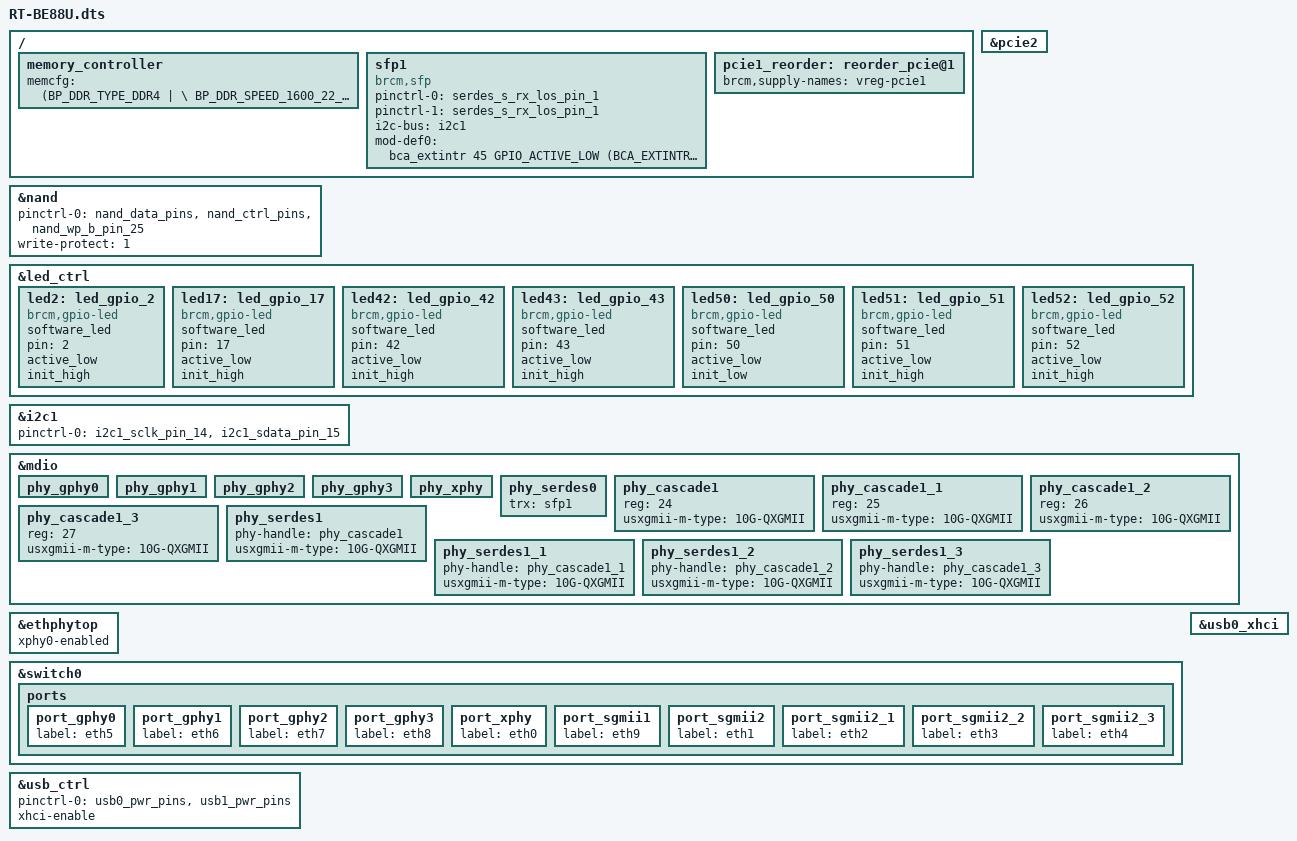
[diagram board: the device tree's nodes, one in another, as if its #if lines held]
#include "6813.dtsi"

/ {
	memory_controller {
		memcfg = <(BP_DDR_TYPE_DDR4       | \
			BP_DDR_SPEED_1600_22_22_22    | \
			BP_DDR_TOTAL_SIZE_2048MB      | \
			BP_DDR_DEVICE_WIDTH_16        | \
			BP_DDR_TOTAL_WIDTH_16BIT      | \
			BP_DDR_TEMP_EXTENDED_ASR      | \
			BP_DDR_SSC_CONFIG_1)>;
	};
/*
    buttons: buttons {
        compatible = "brcm,buttons";
        reset_button {
            ext_irq = <&bca_extintr 13 GPIO_ACTIVE_LOW (BCA_EXTINTR_TYPE_LOW_LEVEL | BCA_EXTINTR_TYPE_SENSE_EDGE)>;
            press {
                print = "Button Press -- Hold for 5s to do restore to default";
            };
            hold {
                rst_to_dflt = <5>;
            };
            release {
                reset = <0>;
            };
        };
        ses_button {
            ext_irq = <&bca_extintr 12 GPIO_ACTIVE_LOW (BCA_EXTINTR_TYPE_LOW_LEVEL | BCA_EXTINTR_TYPE_SENSE_EDGE)>;
            release {
                ses_short_period = <0>;
                ses_long_period = <3>;
            };
        };
    };
*/

    sfp1: sfp1 {
        compatible = "brcm,sfp";
        pinctrl-names = "default", "rx-sd";
        pinctrl-0 = <&serdes_s_rx_los_pin_1>;
        pinctrl-1 = <&serdes_s_rx_los_pin_1>;

        i2c-bus = <&i2c1>;
        mod-def0 = <&bca_extintr 45 GPIO_ACTIVE_LOW (BCA_EXTINTR_TYPE_BOTH_EDGE | BCA_EXTINTR_TYPE_SENSE_EDGE)>;
    };
};

#if defined(CONFIG_BCM_PCIE_HCD) || defined(CONFIG_BCM_PCIE_HCD_MODULE)
#if defined(CONFIG_REGULATOR) && defined(CONFIG_REGULATOR_FIXED_VOLTAGE)
/**********************************************************************/
/* GPIO: Add one define per GPIO (individual or shared) regulator     */
/*       - Skip if no GPIO regulators in use                          */
/**********************************************************************/
#define PCIE1_REG_GPIO    5     /* 5G: SLEEP_1 for vreg_pcie1 node */
#define PCIE2_REG_GPIO    19    /* 2G SLEEP_2 for vreg_pcie2 node */

#include "../bcm_wlan_regulator.dtsi"

/delete-node/ &pcie1;

/ {
    /* pcie core 1 */
    pcie1_reorder: reorder_pcie@1 {
        #define PCIE_ID				1
        #define PCIE_SPI			69
        #define PCIE_ADDR			0x80090000
        #define PCIE_SIZE			PCIE1_REG_SIZE
        #define PCIE_RANGE_ADDR		0xD0000000
        #define PCIE_RANGE_SIZE		0x10000000
        #include "../ip/bcm_pcie_core.dtsi"
    };
};

&pcie1_reorder {
	brcm,supply-names = "vreg-pcie1";
	status = "okay";
};
 
&pcie2 {
	status = "okay";
};
#endif //defined(CONFIG_REGULATOR) && defined(CONFIG_REGULATOR_FIXED_VOLTAGE)
#endif //#if defined(CONFIG_BCM_PCIE_HCD) || defined(CONFIG_BCM_PCIE_HCD_MODULE)

&nand {
	pinctrl-0 = <&nand_data_pins &nand_ctrl_pins &nand_wp_b_pin_25>;
	write-protect = <1>;
	status = "okay";
};

&led_ctrl {
	status="okay";

	/* GPIO LED */
	/* LAN LED */
	led2:led_gpio_2 {
		compatible = "brcm,gpio-led";
		software_led;
		pin = <2>;
		active_low;
		init_high;
	};
	/* 10G WHITE LED */
	led17:led_gpio_17 {
		compatible = "brcm,gpio-led";
		software_led;
		pin = <17>;
		active_low;
		init_high;
	};
	/* WAN WHITE LED */
	led42:led_gpio_42 {
		compatible = "brcm,gpio-led";
		software_led;
		pin = <42>;
		active_low;
		init_high;
	};
	/* WAN RED LED */
	led43:led_gpio_43 {
		compatible = "brcm,gpio-led";
		software_led;
		pin = <43>;
		active_low;
		init_high;
	};
	/* POWER LED */
	led50:led_gpio_50 {
		compatible = "brcm,gpio-led";
		software_led;
		pin = <50>;
		active_low;
		init_low;
	};
	/* USB LED */
	led51:led_gpio_51 {
		compatible = "brcm,gpio-led";
		software_led;
		pin = <51>;
		active_low;
		init_high;
	};
	/* SFP+ LED */
	led52:led_gpio_52 {
		compatible = "brcm,gpio-led";
		software_led;
		pin = <52>;
		active_low;
		init_high;
	};

	/* 2G PA DETECT */
//	led48:led_gpio_48 {
//		compatible = "brcm,gpio-led";
//		software_led;
//		pin = <48>;
//	};

	/* 5G PA DETECT */
//	led53:led_gpio_53 {
///		compatible = "brcm,gpio-led";
//		software_led;
//		pin = <53>;
//	};
};

&i2c1 {
	pinctrl-names = "default";
	pinctrl-0 = <&i2c1_sclk_pin_14 &i2c1_sdata_pin_15>;
	status = "okay";
};

&mdio {
    /* Port PHY mapping:
        port_gphy0 <----> phy_gphy0
        port_gphy1 <----> phy_gphy1
        port_gphy2 <----> phy_gphy2
        port_gphy3 <----> phy_gphy3
        port_xphy <-----> phy_xphy      - Internal 10G PHY
        port_sgmii1 <---> phy_serdes0   - SFP+
        port_sgmii2 <---> phy_serdes1   - phy_cascade1
        port_sgmii2_1 <-> phy_serdes1_1 - phy_cascade1_1
        port_sgmii2_2 <-> phy_serdes1_2 - phy_cascade1_2
        port_sgmii2_3 <-> phy_serdes1_3 - phy_cascade1_3
     */
	phy_gphy0 {
		status = "okay";
	};

	phy_gphy1 {
		status = "okay";
	};

	phy_gphy2 {
		status = "okay";
	};

	phy_gphy3 {
		status = "okay";
	};

	phy_xphy {
		status = "okay";
	};

	phy_serdes0 {
		trx = <&sfp1>;
		status = "okay";
	};

	phy_cascade1 {
		reg = <24>;
		usxgmii-m-type = "10G-QXGMII";  /* types: 10G-SXGMII 10G-DXGMII 10G-QXGMII 5G-SXGMII 5G-DXGMII 2.5G-SXGMII */
		status = "okay";
	};

	phy_cascade1_1 {
		reg = <25>;
		usxgmii-m-type = "10G-QXGMII";  /* types: 10G-SXGMII 10G-DXGMII 10G-QXGMII 5G-SXGMII 5G-DXGMII 2.5G-SXGMII */
		status = "okay";
	};

	phy_cascade1_2 {
		reg = <26>;
		usxgmii-m-type = "10G-QXGMII";  /* types: 10G-SXGMII 10G-DXGMII 10G-QXGMII 5G-SXGMII 5G-DXGMII 2.5G-SXGMII */
		status = "okay";
	};

	phy_cascade1_3 {
		reg = <27>;
		usxgmii-m-type = "10G-QXGMII";  /* types: 10G-SXGMII 10G-DXGMII 10G-QXGMII 5G-SXGMII 5G-DXGMII 2.5G-SXGMII */
		status = "okay";
	};

	phy_serdes1 {
		phy-handle = <&phy_cascade1>;
		usxgmii-m-type = "10G-QXGMII";  /* types: 10G-SXGMII 10G-DXGMII 10G-QXGMII 5G-SXGMII 5G-DXGMII 2.5G-SXGMII */
		status = "okay";
	};

	phy_serdes1_1 {
		phy-handle = <&phy_cascade1_1>;
		usxgmii-m-type = "10G-QXGMII";  /* types: 10G-SXGMII 10G-DXGMII 10G-QXGMII 5G-SXGMII 5G-DXGMII 2.5G-SXGMII */
		status = "okay";
	};

	phy_serdes1_2 {
		phy-handle = <&phy_cascade1_2>;
		usxgmii-m-type = "10G-QXGMII";  /* types: 10G-SXGMII 10G-DXGMII 10G-QXGMII 5G-SXGMII 5G-DXGMII 2.5G-SXGMII */
		status = "okay";
	};
    
	phy_serdes1_3 {
		phy-handle = <&phy_cascade1_3>;
		usxgmii-m-type = "10G-QXGMII";  /* types: 10G-SXGMII 10G-DXGMII 10G-QXGMII 5G-SXGMII 5G-DXGMII 2.5G-SXGMII */
		status = "okay";
	};

};

&ethphytop {
    xphy0-enabled;
    status = "okay";
};

&switch0 {
	ports {
		port_gphy0 {
			status = "okay";
			label = "eth5";
		};

		port_gphy1 {
			status = "okay";
			label = "eth6";
		};

		port_gphy2 {
			status = "okay";
			label = "eth7";
		};

		port_gphy3 {
			status = "okay";
			label = "eth8";
		};

		port_xphy {
			status = "okay";
			label = "eth0";
		};

		port_sgmii1 {
			status = "okay";
			label = "eth9";
		};

                port_sgmii2 {
                        status = "okay";
			label = "eth1";
                };
                
                port_sgmii2_1 {
                        status = "okay";
			label = "eth2";
                };
                
                port_sgmii2_2 {
                        status = "okay";
			label = "eth3";
                };
                
                port_sgmii2_3 {
                        status = "okay";
			label = "eth4";
                };

	};
};

&usb_ctrl {
	pinctrl-names = "default";
	pinctrl-0 = <&usb0_pwr_pins &usb1_pwr_pins>;
	status = "okay";
	xhci-enable;
};
&usb0_xhci {
	status = "okay";
};
